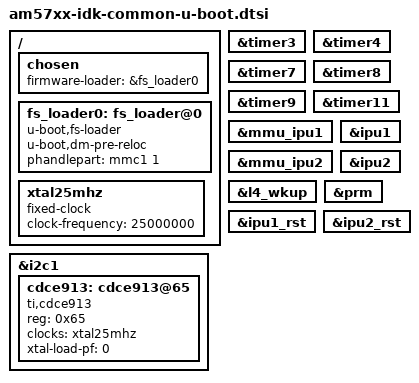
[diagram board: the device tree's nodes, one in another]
// SPDX-License-Identifier: GPL-2.0+
/*
 * Copyright (C) 2019 Texas Instruments Incorporated - http://www.ti.com/
 */
#include "omap5-u-boot.dtsi"

/ {
	chosen {
		firmware-loader = &fs_loader0;
	};

	fs_loader0: fs_loader@0 {
		u-boot,dm-pre-reloc;
		compatible = "u-boot,fs-loader";
		phandlepart = <&mmc1 1>;
	};

	xtal25mhz: xtal25mhz {
		compatible = "fixed-clock";
		#clock-cells = <0>;
		clock-frequency = <25000000>;
	};
};

&i2c1 {
	cdce913: cdce913@65 {
		compatible = "ti,cdce913";
		reg = <0x65>;
		clocks = <&xtal25mhz>;
		#clock-cells = <1>;
		xtal-load-pf = <0>;
	};
};

&timer3 {
	u-boot,dm-spl;
};

&timer4 {
	u-boot,dm-spl;
};

&timer7 {
	u-boot,dm-spl;
};

&timer8 {
	u-boot,dm-spl;
};

&timer9 {
	u-boot,dm-spl;
};

&timer11 {
	u-boot,dm-spl;
};

&mmu_ipu1 {
	u-boot,dm-spl;
};

&mmu_ipu2 {
	u-boot,dm-spl;
};

&ipu1 {
	status = "okay";
	u-boot,dm-spl;
};

&ipu2 {
	status = "okay";
	u-boot,dm-spl;
};

&l4_wkup {
	u-boot,dm-spl;
};

&prm {
	u-boot,dm-spl;
};

&ipu1_rst {
	u-boot,dm-spl;
};

&ipu2_rst {
	u-boot,dm-spl;
};
